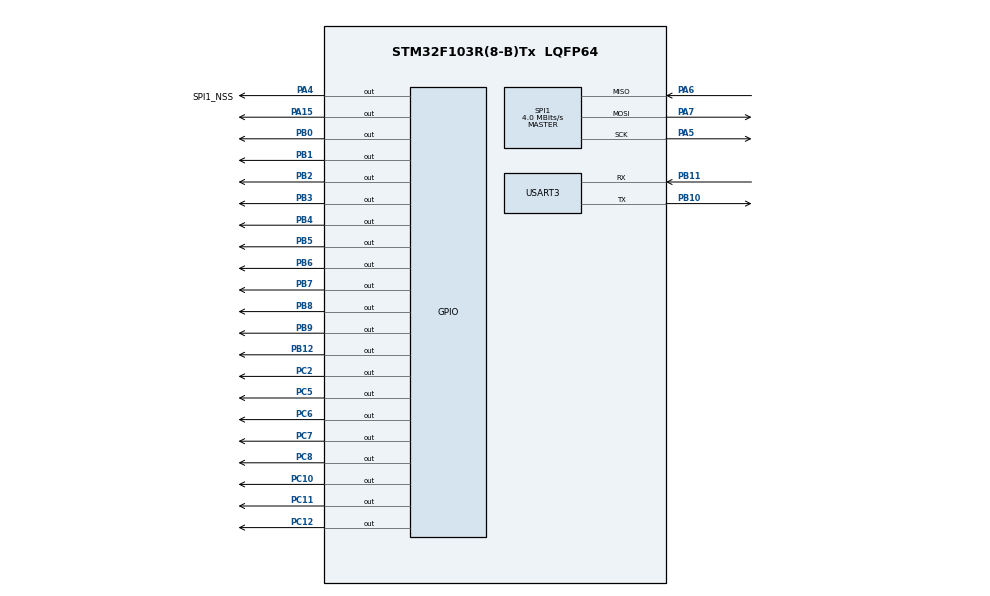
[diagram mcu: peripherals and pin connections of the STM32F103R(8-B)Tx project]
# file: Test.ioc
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Dma.Request0=USART3_RX
Dma.USART3_RX.0.Direction=DMA_PERIPH_TO_MEMORY
Dma.USART3_RX.0.Instance=DMA1_Channel3
Dma.USART3_RX.0.MemDataAlignment=DMA_MDATAALIGN_BYTE
Dma.USART3_RX.0.MemInc=DMA_MINC_ENABLE
Dma.USART3_RX.0.Mode=DMA_NORMAL
Dma.USART3_RX.0.PeriphDataAlignment=DMA_PDATAALIGN_BYTE
Dma.USART3_RX.0.PeriphInc=DMA_PINC_DISABLE
Dma.USART3_RX.0.Priority=DMA_PRIORITY_LOW
Mcu.Family=STM32F1
Mcu.Name=STM32F103R(8-B)Tx
Mcu.Package=LQFP64
NVIC.DMA1_Channel3_IRQn=true\:0\:0\:false\:false\:true\:false\:true
NVIC.PriorityGroup=NVIC_PRIORITYGROUP_4
NVIC.TIM1_BRK_IRQn=true\:0\:0\:false\:false\:true\:true\:true
NVIC.TIM2_IRQn=true\:0\:0\:false\:false\:true\:true\:true
NVIC.USART3_IRQn=true\:0\:0\:false\:false\:true\:true\:true
PA13.Mode=Serial_Wire
PA13.Signal=SYS_JTMS-SWDIO
PA14.Mode=Serial_Wire
PA14.Signal=SYS_JTCK-SWCLK
PA15.Signal=GPIO_Output
PA4.GPIO_Label=SPI1_NSS
PA4.Signal=GPIO_Output
PA5.Mode=Full_Duplex_Master
PA5.Signal=SPI1_SCK
PA6.Mode=Full_Duplex_Master
PA6.Signal=SPI1_MISO
PA7.Mode=Full_Duplex_Master
PA7.Signal=SPI1_MOSI
PB0.Signal=GPIO_Output
PB1.Signal=GPIO_Output
PB10.Mode=Asynchronous
PB10.Signal=USART3_TX
PB11.Mode=Asynchronous
PB11.Signal=USART3_RX
PB12.Signal=GPIO_Output
PB2.Signal=GPIO_Output
PB3.Signal=GPIO_Output
PB4.Signal=GPIO_Output
PB5.Signal=GPIO_Output
PB6.Signal=GPIO_Output
PB7.Signal=GPIO_Output
PB8.Signal=GPIO_Output
PB9.Signal=GPIO_Output
PC10.Signal=GPIO_Output
PC11.Signal=GPIO_Output
PC12.Signal=GPIO_Output
PC2.Signal=GPIO_Output
PC5.Signal=GPIO_Output
PC6.Signal=GPIO_Output
PC7.Signal=GPIO_Output
PC8.Signal=GPIO_Output
PD0-OSC_IN.Mode=HSE-External-Oscillator
PD0-OSC_IN.Signal=RCC_OSC_IN
PD1-OSC_OUT.Mode=HSE-External-Oscillator
PD1-OSC_OUT.Signal=RCC_OSC_OUT
ProjectManager.HeapSize=0x200
ProjectManager.StackSize=0x400
ProjectManager.TargetToolchain=MDK-ARM V5.32
RCC.APB1Freq_Value=8000000
RCC.APB1TimFreq_Value=8000000
RCC.APB2Freq_Value=8000000
RCC.SYSCLKSource=RCC_SYSCLKSOURCE_HSE
SPI1.CalculateBaudRate=4.0 MBits/s
SPI1.Direction=SPI_DIRECTION_2LINES
SPI1.Mode=SPI_MODE_MASTER
SPI1.VirtualType=VM_MASTER
TIM1.Period=100
TIM1.Prescaler=8
TIM2.Period=99
TIM2.Prescaler=7
USART3.VirtualMode=VM_ASYNC
VP_RTC_VS_RTC_Activate.Mode=RTC_Enabled
VP_TIM1_VS_ClockSourceINT.Mode=Internal
VP_TIM2_VS_ClockSourceINT.Mode=Internal
board=custom

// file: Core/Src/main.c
/* USER CODE BEGIN Header */
/**
  ******************************************************************************
  * @file           : main.c
  * @brief          : Main program body
  ******************************************************************************
  * @attention
  *
  * <h2><center>&copy; Copyright (c) 2021 STMicroelectronics.
  * All rights reserved.</center></h2>
  *
  * This software component is licensed by ST under BSD 3-Clause license,
  * the "License"; You may not use this file except in compliance with the
  * License. You may obtain a copy of the License at:
  *                        opensource.org/licenses/BSD-3-Clause
  *
  ******************************************************************************
  */
/* USER CODE END Header */
#include "main.h"
#include "dma.h"
#include "rtc.h"
#include "spi.h"
#include "tim.h"
#include "usart.h"
#include "gpio.h"

/* USER CODE BEGIN Includes */
#include "W25Qxx.h"
#include "Timer.h"
/* USER CODE END Includes */

void SystemClock_Config(void);

/* USER CODE BEGIN 0 */
uint8_t offset[52] = "+05-10";
uint8_t buffer[52];
int offset_int[17] = {9, 0, 9, -9, 0, 0, -18, 18};
uint8_t uart_buffer[100];
uint8_t recvTemp;
//uint8_t aTxStartMessages[6] = "12345";
//uint8_t aRxBuffer[6];
/* USER CODE END 0 */

int main(void)
{

  /* MCU Configuration--------------------------------------------------------*/

  /* Reset of all peripherals, Initializes the Flash interface and the Systick. */
  HAL_Init();

  /* Configure the system clock */
  SystemClock_Config();

  /* Initialize all configured peripherals */
  MX_GPIO_Init();
  MX_RTC_Init();
  MX_TIM1_Init();
  MX_TIM2_Init();
  MX_SPI1_Init();
  MX_DMA_Init();
  MX_USART3_UART_Init();
  /* USER CODE BEGIN 2 */
  //HAL_UART_Receive_DMA(&huart3, &recvTemp, 1);
  HAL_UART_Receive_DMA(&huart3, uart_buffer, 1);
	HAL_TIM_Base_Start_IT(&htim2);
	BSP_W25Qx_Init();
	servo_init();
	// BSP_W25Qx_Write(offset, W25Q128FV_FLASH_SIZE-2000, sizeof(offset));
	/*
	HAL_Delay(50);
	BSP_W25Qx_Read(buffer, W25Q128FV_FLASH_SIZE-2000, sizeof(buffer));
	  //BSP_W25Qx_Write(aTxStartMessages, W25Q128FV_FLASH_SIZE-2000, sizeof(aTxStartMessages));
	  //HAL_Delay(50);
	  //BSP_W25Qx_Read(aRxBuffer, W25Q128FV_FLASH_SIZE-2000, sizeof(aTxStartMessages));
	  for(int i = 0; i < 51; i = i + 3) {
		if(buffer[i] == '+') {
			offset_int[i / 3] = (buffer[i + 1] - '0') * 10 + buffer[i + 2] - '0';
		}
		else if(buffer[i] == '-') {
			offset_int[i / 3] = -(buffer[i + 1] - '0') * 10 - buffer[i + 2] - '0';
		}
	  }*/
  /* USER CODE END 2 */

  /* Infinite loop */
  while (1)
  {

  }
}

void SystemClock_Config(void)
{
  RCC_OscInitTypeDef RCC_OscInitStruct = {0};
  RCC_ClkInitTypeDef RCC_ClkInitStruct = {0};
  RCC_PeriphCLKInitTypeDef PeriphClkInit = {0};

  /** Initializes the RCC Oscillators according to the specified parameters
  * in the RCC_OscInitTypeDef structure.
  */
  RCC_OscInitStruct.OscillatorType = RCC_OSCILLATORTYPE_LSI|RCC_OSCILLATORTYPE_HSE;
  RCC_OscInitStruct.HSEState = RCC_HSE_ON;
  RCC_OscInitStruct.LSIState = RCC_LSI_ON;
  RCC_OscInitStruct.PLL.PLLState = RCC_PLL_NONE;
  if (HAL_RCC_OscConfig(&RCC_OscInitStruct) != HAL_OK)
  {
    Error_Handler();
  }
  /** Initializes the CPU, AHB and APB buses clocks
  */
  RCC_ClkInitStruct.ClockType = RCC_CLOCKTYPE_HCLK|RCC_CLOCKTYPE_SYSCLK
                              |RCC_CLOCKTYPE_PCLK1|RCC_CLOCKTYPE_PCLK2;
  RCC_ClkInitStruct.SYSCLKSource = RCC_SYSCLKSOURCE_HSE;
  RCC_ClkInitStruct.AHBCLKDivider = RCC_SYSCLK_DIV1;
  RCC_ClkInitStruct.APB1CLKDivider = RCC_HCLK_DIV1;
  RCC_ClkInitStruct.APB2CLKDivider = RCC_HCLK_DIV1;

  if (HAL_RCC_ClockConfig(&RCC_ClkInitStruct, FLASH_LATENCY_0) != HAL_OK)
  {
    Error_Handler();
  }
  PeriphClkInit.PeriphClockSelection = RCC_PERIPHCLK_RTC;
  PeriphClkInit.RTCClockSelection = RCC_RTCCLKSOURCE_LSI;
  if (HAL_RCCEx_PeriphCLKConfig(&PeriphClkInit) != HAL_OK)
  {
    Error_Handler();
  }
}

void Error_Handler(void)
{
  __disable_irq();
  while (1)
  {
  }
}

/************************ (C) COPYRIGHT STMicroelectronics *****END OF FILE****/
